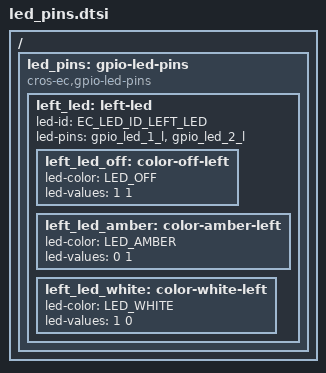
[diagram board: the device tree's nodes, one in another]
/* Copyright 2023 The ChromiumOS Authors
 * Use of this source code is governed by a BSD-style license that can be
 * found in the LICENSE file.
 */

/ {
	led_pins: gpio-led-pins {
		compatible = "cros-ec,gpio-led-pins";

		left_led: left-led {
			led-id = "EC_LED_ID_LEFT_LED";
			led-pins = <&gpio_led_1_l &gpio_led_2_l>;
			left_led_off: color-off-left {
				led-color = "LED_OFF";
				led-values = <1 1>;
			};

			left_led_amber: color-amber-left {
				led-color = "LED_AMBER";
				led-values = <0 1>;
			};

			left_led_white: color-white-left {
				led-color = "LED_WHITE";
				led-values = <1 0>;
			};
		};
	};
};
